# STM32H523 register map
File version: 1.2
CPU: CM33 r0p0, little endian, MPU, FPU, 4 interrupt priority bits
Registers are 32-bit, read-write, reset 0x0 unless marked. A register's access mark holds for its fields unless they carry their own. Offsets are from the block's base; [hi:lo] are bit positions; {n}, {i} and the like mark numbered series; 'fields as' and 'values as' point back to an identical list.

## TIM6 — TIM6 address block description
Base 0x40001000
Same registers: TIM6_S 0x50001000
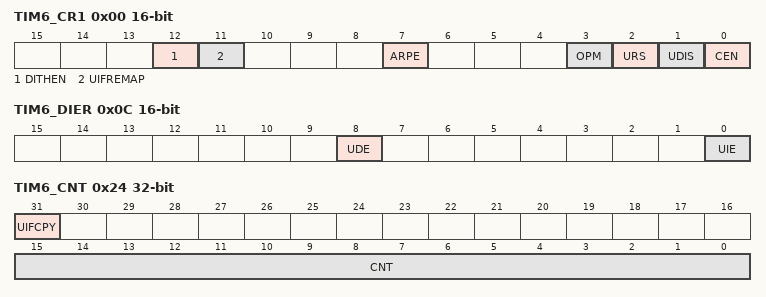
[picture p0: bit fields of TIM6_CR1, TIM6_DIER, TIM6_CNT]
0x00 TIM6_CR1 16-bit — TIM6 control register 1
  [12] DITHEN — Dithering enable
    0=Dithering disabled; 1=Dithering enabled
  [11] UIFREMAP — UIF status bit remapping
    0=No remapping; 1=Remapping enabled
  [7] ARPE — Auto-reload preload enable
    0=TIMx_ARR register is not buffered; 1=TIMx_ARR register is buffered
  [3] OPM — One-pulse mode
    0=Counter is not stopped at update event; 1=Counter stops counting at the next update event (clearing the CEN bit)
  [2] URS — Update request source
    0=Any of the following events generates an update interrupt or DMA request if enabled; 1=Only counter overflow/underflow generates an update interrupt or DMA request if enabled
  [1] UDIS — Update disable
    0=UEV enabled; 1=UEV disabled
  [0] CEN — Counter enable
    0=Counter disabled; 1=Counter enabled
0x04 TIM6_CR2 16-bit — TIM6 control register 2
  [6:4] MMS — Master mode selection
    0=Reset - the UG bit from the TIMx_EGR register is used as a trigger output (tim_trgo); 1=Enable - the Counter enable signal, tim_cnt_en, is used as a trigger output (tim_trgo); 2=Update - The update event is selected as a trigger output (tim_trgo)
0x0C TIM6_DIER 16-bit — TIM6 DMA/Interrupt enable register
  [8] UDE — Update DMA request enable
    0=Update DMA request disabled; 1=Update DMA request enabled
  [0] UIE — Update interrupt enable
    0=Update interrupt disabled; 1=Update interrupt enabled
0x10 TIM6_SR 16-bit — TIM6 status register
  [0] UIF — Update interrupt flag
    0=No update occurred; 1=Update interrupt pending
0x14 TIM6_EGR 16-bit wo — TIM6 event generation register
  [0] UG — Update generation
    0=No action; 1=Re-initializes the timer counter and generates an update of the registers
0x24 TIM6_CNT — TIM6 counter
  [31] UIFCPY ro — UIF copy
  [15:0] CNT — Counter value
0x28 TIM6_PSC 16-bit — TIM6 prescaler
  [15:0] PSC — Prescaler value
0x2C TIM6_ARR reset 0xFFFF — TIM6 auto-reload register
  [19:0] ARR — Auto-reload value

## TIM7 — TIM7 address block description
Base 0x40001400
Same registers: TIM7_S 0x50001400
Registers as TIM6 (with TIM6 read as TIM7).

## USBSRAM — USBSRAM address block description
Base 0x40016400
Same registers: USBSRAM_S 0x50016400
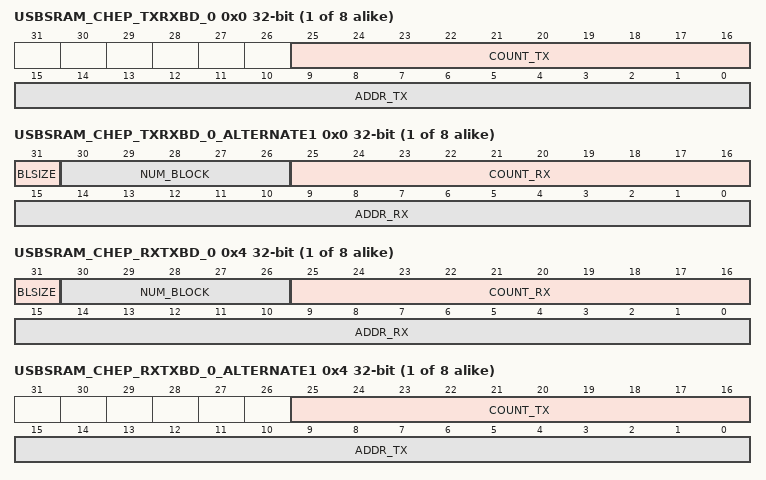
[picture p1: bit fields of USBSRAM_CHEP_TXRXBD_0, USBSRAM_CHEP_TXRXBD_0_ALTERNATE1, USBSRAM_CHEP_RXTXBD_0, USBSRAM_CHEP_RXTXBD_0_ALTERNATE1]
{0x0+8i} USBSRAM_CHEP_TXRXBD_{i} reset not defined (i=0..7) — Channel/endpoint transmit buffer descriptor {i}
  [25:16] COUNT_TX — Transmission byte count
  [15:0] ADDR_TX — Transmission buffer address
{0x0+8i} USBSRAM_CHEP_TXRXBD_{i}_ALTERNATE1 reset not defined (alternate view of USBSRAM_CHEP_TXRXBD_{i}) (i=0..7) — Channel/endpoint receive buffer descriptor {i}
  [31] BLSIZE — Block size
  [30:26] NUM_BLOCK — Number of blocks
  [25:16] COUNT_RX ro — Reception byte count
  [15:0] ADDR_RX — Reception buffer address
{0x4+8i} USBSRAM_CHEP_RXTXBD_{i} reset not defined (i=0..7) — Channel/endpoint receive buffer descriptor {i}
  fields as USBSRAM_CHEP_TXRXBD_0_ALTERNATE1
{0x4+8i} USBSRAM_CHEP_RXTXBD_{i}_ALTERNATE1 reset not defined (alternate view of USBSRAM_CHEP_RXTXBD_{i}) (i=0..7) — Channel/endpoint transmit buffer descriptor {i}
  fields as USBSRAM_CHEP_TXRXBD_0

## VREFBUF — VREFBUF address block description
Base 0x44007400
Same registers: VREFBUF_S 0x54007400
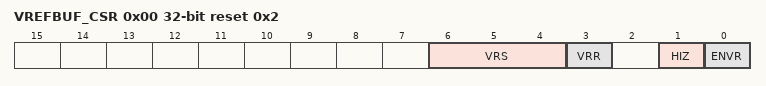
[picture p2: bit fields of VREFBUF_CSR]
0x00 VREFBUF_CSR reset 0x2 — VREFBUF control and status register
  [6:4] VRS — Voltage reference scale
  [3] VRR ro — Voltage reference buffer ready
    0=the voltage reference buffer output is not ready; 1=the voltage reference buffer output reached the requested level
  [1] HIZ — High impedance mode
    0=Vless thansub>REF+less than/sub> pin is internally connected to the voltage reference buffer output; 1=Vless thansub>REF+less than/sub> pin is high impedance
  [0] ENVR — Voltage reference buffer mode enable
    0=Internal voltage reference mode disable (external voltage reference mode); 1=Internal voltage reference mode (reference buffer enable or hold mode) enable
0x04 VREFBUF_CCR (reset mask 0xFFFFFF00) — VREFBUF calibration control register
  [5:0] TRIM — Trimming code

## WWDG — WWDG address block description
Base 0x40002C00
Same registers: WWDG_S 0x50002C00
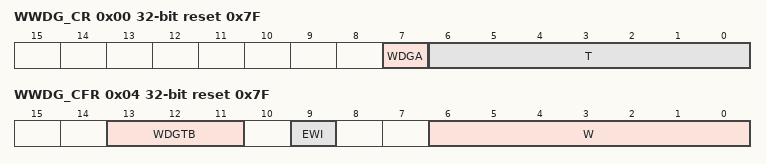
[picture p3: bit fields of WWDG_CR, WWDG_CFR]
0x00 WWDG_CR reset 0x7F — WWDG control register
  [7] WDGA — Activation bit
    0=Watchdog disabled; 1=Watchdog enabled
  [6:0] T — 7-bit counter (MSB to LSB)
0x04 WWDG_CFR reset 0x7F — WWDG configuration register
  [13:11] WDGTB — Timer base
    0=CK counter clock (PCLK div 4096) div 1; 1=CK counter clock (PCLK div 4096) div 2; 2=CK counter clock (PCLK div 4096) div 4; 3=CK counter clock (PCLK div 4096) div 8; 4=CK counter clock (PCLK div 4096) div 16; 5=CK counter clock (PCLK div 4096) div 32; 6=CK counter clock (PCLK div 4096) div 64; 7=CK counter clock (PCLK div 4096) div 128
  [9] EWI — Early wake-up interrupt enable
  [6:0] W — 7-bit window value
0x08 WWDG_SR — WWDG status register
  [0] EWIF — Early wake-up interrupt flag
